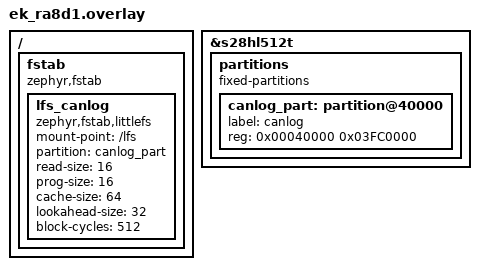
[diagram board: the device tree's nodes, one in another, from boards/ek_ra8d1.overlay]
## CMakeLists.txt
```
# SPDX-License-Identifier: Apache-2.0
#
# Phase 2D: littlefs on the Octo-SPI flash + batched CAN-frame logger
# (build-only, no board). Board target: ek_ra8d1. The littlefs partition and
# fstab node are defined in boards/ek_ra8d1.overlay (auto-applied by filename).

cmake_minimum_required(VERSION 3.28.0)

find_package(Zephyr REQUIRED HINTS $ENV{ZEPHYR_BASE})
project(flash_log)

target_include_directories(app PRIVATE include)
target_sources(app PRIVATE
  src/main.c
  src/flash_log.c
)
```

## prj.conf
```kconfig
# Phase 2D - littlefs on Octo-SPI flash + batched CAN logger. Every symbol
# checked against the workspace before being added.
#
#   CONFIG_FLASH               -> drivers/flash/Kconfig
#   CONFIG_FLASH_MAP           -> subsys/storage/flash_map/Kconfig. Required by
#                                 CONFIG_FS_LITTLEFS_FMP_DEV (littlefs on flash).
#   CONFIG_FLASH_PAGE_LAYOUT   -> drivers/flash/Kconfig:169. "default
#                                 FLASH_HAS_PAGE_LAYOUT"; the OSPI-B NOR driver
#                                 selects FLASH_HAS_PAGE_LAYOUT so this is
#                                 effectively automatic - set explicitly.
#   CONFIG_FLASH_RENESAS_RA_OSPI_B -> drivers/flash/Kconfig.renesas_ra_ospi.
#                                 "default y" when the &s28hl512t node
#                                 (compatible renesas,ra-ospi-b-nor) is enabled
#                                 by the board. Implements erase/write/read +
#                                 page_layout for the S28HX512T.
#   CONFIG_FILE_SYSTEM / _LITTLEFS -> subsys/fs/Kconfig + Kconfig.littlefs.
#                                 LITTLEFS needs the modules/fs/littlefs module
#                                 (present in this workspace).
#   CONFIG_RING_BUFFER        -> lib/os/Kconfig. SRAM staging ring in flash_log.c.
#   CONFIG_MAIN_STACK_SIZE=8192 -> fs_dirent / fs_statvfs plus the 1 KiB drain
#                                 buffer used by flash_log_stop() on the main
#                                 thread (the littlefs sample uses 4096 with no
#                                 extra stack buffers).

CONFIG_FLASH=y
CONFIG_FLASH_MAP=y
CONFIG_FLASH_PAGE_LAYOUT=y
CONFIG_FLASH_RENESAS_RA_OSPI_B=y

CONFIG_FILE_SYSTEM=y
CONFIG_FILE_SYSTEM_LITTLEFS=y

CONFIG_RING_BUFFER=y

CONFIG_MAIN_STACK_SIZE=8192

CONFIG_LOG=y
CONFIG_LOG_DEFAULT_LEVEL=3

# TEMP (bring-up diagnostic): surface which step of the OSPI SPI-mode init
# fails - the reasons are LOG_DBG inside flash_renesas_ra_ospi_b.c.
CONFIG_FLASH_LOG_LEVEL_DBG=y
```

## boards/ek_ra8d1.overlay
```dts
/*
 * App-local devicetree overlay for apps/flash_log on the EK-RA8D1.
 * Zephyr auto-applies <app>/boards/<board>.overlay by filename.
 *
 * Re-partitions the on-board 64 MB Octo-SPI NOR flash (U3, S28HL512T, node
 * &s28hl512t, controller &ospi0) for a littlefs log store. The stock board dts
 * gives it one whole-chip partition labelled "nor"; we replace that.
 *
 * Erase geometry (from the board node's pages_layout, verified in
 * zephyr/boards/renesas/ek_ra8d1/ek_ra8d1.dts):
 *     0x00000000 .. 0x00020000   32 x 4 KiB sectors
 *     0x00020000 .. 0x00040000   1 x 128 KiB sector
 *     0x00040000 .. 0x04000000   255 x 256 KiB sectors
 * Zephyr's littlefs flash backend uses the LARGEST page size that overlaps the
 * partition and assumes that erase size works across the whole partition
 * (subsys/fs/littlefs_fs.c get_block_size()). So the littlefs partition starts
 * at 0x40000 to sit entirely in the uniform 256 KiB-sector region; the first
 * 256 KiB is left unallocated (reserved for a future NVS/settings partition).
 */

&s28hl512t {
	/delete-node/ partitions;

	partitions {
		compatible = "fixed-partitions";
		#address-cells = <1>;
		#size-cells = <1>;

		canlog_part: partition@40000 {
			label = "canlog";
			/* 0x00040000 .. 0x04000000  (64 MiB - 256 KiB = 63.75 MiB) */
			reg = <0x00040000 0x03FC0000>;
		};
	};
};

/ {
	fstab {
		compatible = "zephyr,fstab";

		lfs_canlog: lfs_canlog {
			compatible = "zephyr,fstab,littlefs";
			mount-point = "/lfs";
			partition = <&canlog_part>;
			/* read/prog match the driver's write-block-size=1; cache 64
			 * is a factor of the 256 KiB block size and a multiple of
			 * prog-size, per the binding's constraints.
			 */
			read-size = <16>;
			prog-size = <16>;
			cache-size = <64>;
			lookahead-size = <32>;
			block-cycles = <512>;
			/* No `automount;` - flash_log.c mounts explicitly so it
			 * owns the mount/unmount lifecycle.
			 */
		};
	};
};
```

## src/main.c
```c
/*
 * SPDX-License-Identifier: Apache-2.0
 *
 * Phase 2D demo entry point (build-only, no board).
 *
 * Exercises the littlefs CAN logger so the whole module is compiled and
 * linked: mount -> start -> feed synthetic frames -> flush -> stop. None of
 * this runs without hardware (the OSPI flash and littlefs are never actually
 * touched in this session); there is no flashing in this phase.
 */

#include <errno.h>

#include <zephyr/kernel.h>
#include <zephyr/logging/log.h>

#include "flash_log.h"

LOG_MODULE_REGISTER(main, LOG_LEVEL_INF);

/* bit4 = RTR, matching flash_log_frame.flags / CAN_FRAME_* */
#define FRAME_FLAG_FDF 0x01
#define FRAME_FLAG_BRS 0x02

int main(void)
{
	struct flash_log_stats st;
	int ret;

	ret = flash_log_init();
	if (ret != 0) {
		LOG_ERR("flash_log_init failed: %d", ret);
		return 0;
	}

	ret = flash_log_start();
	if (ret != 0) {
		LOG_ERR("flash_log_start failed: %d", ret);
		return 0;
	}

	/* Simulate the "start logging" button having been pressed and a short
	 * burst of bus traffic arriving. flash_log_record() would normally be
	 * called from the CAN RX ISR (Phase 2A) with k_uptime_ticks() captured
	 * there.
	 */
	for (uint32_t i = 0; i < 200; i++) {
		struct flash_log_frame f = {
			.id = 0x100 + (i & 0x7F),
			.flags = FRAME_FLAG_FDF | FRAME_FLAG_BRS,
			.dlc = 8,
			.timestamp = k_uptime_ticks(),
		};

		for (int b = 0; b < 8; b++) {
			f.data[b] = (uint8_t)(i + b);
		}

		ret = flash_log_record(&f);
		if (ret == -ENOSPC) {
			LOG_WRN("ring full at frame %u (writer would catch up)", i);
		}
	}

	/* "Periodic flush trigger" (Phase 2B timer would call this). */
	flash_log_flush();
	k_sleep(K_MSEC(50));

	ret = flash_log_stop();
	if (ret != 0) {
		LOG_ERR("flash_log_stop failed: %d", ret);
	}

	flash_log_get_stats(&st);
	LOG_INF("stats: queued=%u dropped=%u bytes=%u flushes=%u werr=%u",
		st.records_queued, st.records_dropped, st.bytes_written,
		st.flush_count, st.write_errors);

	return 0;
}
```

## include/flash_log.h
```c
/*
 * SPDX-License-Identifier: Apache-2.0
 *
 * Phase 2D - persistent CAN-frame logger on the Octo-SPI flash (littlefs).
 *
 * Design points (see PROMPTS.md Phase 2D and STATE.md decisions):
 *   - Storage: littlefs on partition "canlog" of the on-board 64 MB OSPI NOR
 *     (&s28hl512t), mounted at /lfs. Partition + fstab node are in the app
 *     overlay.
 *   - Batched writes, NOT one flash write per frame: flash_log_record() only
 *     copies a serialised record into an SRAM ring buffer. A dedicated writer
 *     thread drains the ring to the open file in >= chunk-sized fs_write()s.
 *     This bounds flash wear and keeps the producer (a CAN RX ISR, later)
 *     non-blocking.
 *   - SRAM ring, not SDRAM: the board's 64 MB SDRAM is populated (SW1-7 ON by
 *     default) but the decisions log keeps the logger on on-chip SRAM unless
 *     SRAM proves insufficient for burst absorption. SDRAM stays a documented
 *     future option (bump FLASH_LOG_RING_SIZE and place the ring in the SDRAM
 *     region).
 *   - Lossy by design: a full ring drops the frame and counts it rather than
 *     stalling the caller.
 *
 * Independent of the Phase 2A/2B/2C modules - it only takes a plain frame
 * struct. Wiring flash_log_record() to the CAN RX path and flash_log_flush()
 * to the Phase 2B periodic timer is an integration step for when hardware is
 * available.
 *
 * On-disk format: see the "CLB1" description in flash_log.c.
 */

#ifndef FLASH_LOG_FLASH_LOG_H_
#define FLASH_LOG_FLASH_LOG_H_

#include <stdbool.h>
#include <stdint.h>

#ifdef __cplusplus
extern "C" {
#endif

/** SRAM staging ring size. Raise (and relocate to SDRAM) for heavier bursts. */
#define FLASH_LOG_RING_SIZE 8192

/**
 * @brief One CAN(-FD) frame to be logged.
 *
 * Field semantics match the Phase 2A struct canlog_frame and the Phase 2C
 * struct clp_can_frame (flags bits = Zephyr CAN_FRAME_*).
 */
struct flash_log_frame {
	uint32_t id;
	uint8_t  flags;       /* bit0 FDF, bit1 BRS, bit2 ESI, bit3 IDE, bit4 RTR */
	uint8_t  dlc;         /* raw DLC; byte count via the CAN-FD DLC table    */
	uint8_t  data[64];
	uint64_t timestamp;   /* k_uptime_ticks() sampled by the caller          */
};

struct flash_log_stats {
	uint32_t records_queued;   /* accepted into the ring        */
	uint32_t records_dropped;  /* ring full                     */
	uint32_t bytes_written;    /* bytes fs_write()n to the file */
	uint32_t flush_count;      /* fs_sync() calls               */
	uint32_t write_errors;     /* fs_write()/fs_sync() failures */
};

/**
 * @brief Mount the littlefs log store at /lfs and start the writer thread.
 *
 * @retval 0        mounted
 * @retval -ENODEV  flash device / partition not available
 * @retval <0       errno from fs_mount()
 */
int flash_log_init(void);

/**
 * @brief Open a new log file "/lfs/log_<uptime_ticks>.clb" and write its header.
 *
 * @retval 0         logging started
 * @retval -EALREADY a log file is already open
 * @retval <0        errno from fs_open()/fs_write()
 */
int flash_log_start(void);

/** @return true while a log file is open. */
bool flash_log_active(void);

/**
 * @brief Queue a frame for logging (non-blocking).
 *
 * @retval 0        queued
 * @retval -ENOSPC  ring full, frame dropped (counted)
 * @retval -EPERM   logging not started
 */
int flash_log_record(const struct flash_log_frame *f);

/** Ask the writer thread to drain the ring and fs_sync() now. Non-blocking. */
int flash_log_flush(void);

/**
 * @brief Drain the ring, fs_sync(), and close the current log file.
 *
 * @retval 0        stopped
 * @retval -EALREADY no log file open
 * @retval <0       errno from fs_close()
 */
int flash_log_stop(void);

void flash_log_get_stats(struct flash_log_stats *out);

#ifdef __cplusplus
}
#endif

#endif /* FLASH_LOG_FLASH_LOG_H_ */
```

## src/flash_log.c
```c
/*
 * SPDX-License-Identifier: Apache-2.0
 *
 * Phase 2D - littlefs CAN-frame logger. Build-only; nothing is flashed and the
 * filesystem is never actually mounted in this session (no board).
 *
 * On-disk format ("CLB1"), little-endian, one file per logging session:
 *
 *   File header (16 bytes):
 *     off 0  : magic  "CLB1"                (4 bytes)
 *     off 4  : format_version  u16          (= 1)
 *     off 6  : header_length   u16          (= 16)
 *     off 8  : start_timestamp u64          (k_uptime_ticks() at flash_log_start)
 *
 *   Then a stream of variable-length records:
 *     off 0  : marker  u8   (= 0xC5, lets an offline tool resync)
 *     off 1  : flags   u8   (CAN_FRAME_* bits: FDF|BRS|ESI|IDE|RTR)
 *     off 2  : dlc     u8   (raw DLC)
 *     off 3  : n       u8   (data byte count = dlc_to_bytes(dlc), 0 if RTR)
 *     off 4  : can_id  u32
 *     off 8  : timestamp u64
 *     off 16 : data    n bytes
 *   record length = 16 + n.
 */

#include <errno.h>
#include <stdio.h>
#include <string.h>

#include <zephyr/kernel.h>
#include <zephyr/fs/fs.h>
#include <zephyr/fs/littlefs.h>
#include <zephyr/sys/byteorder.h>
#include <zephyr/sys/ring_buffer.h>
#include <zephyr/logging/log.h>

#include "flash_log.h"

LOG_MODULE_REGISTER(flash_log, LOG_LEVEL_INF);

/* fstab node from boards/ek_ra8d1.overlay. */
FS_FSTAB_DECLARE_ENTRY(DT_NODELABEL(lfs_canlog));
#define LOG_MP (&FS_FSTAB_ENTRY(DT_NODELABEL(lfs_canlog)))

BUILD_ASSERT(DT_NODE_EXISTS(DT_NODELABEL(lfs_canlog)),
	     "missing lfs_canlog fstab node - check the app overlay");

#define WRITE_CHUNK       1024U   /* max bytes per fs_write() batch  */
#define WRITER_IDLE_MS    500     /* drain accumulated data this often */
#define WRITER_STACK_SIZE 6144
#define STOP_WAIT_MS      2000

#define REC_MARKER 0xC5U
#define REC_FIXED  16U           /* marker+flags+dlc+n + id(4) + ts(8) */

RING_BUF_DECLARE(log_rb, FLASH_LOG_RING_SIZE);
static struct k_spinlock rb_lock;

static struct fs_file_t log_file;
static K_MUTEX_DEFINE(file_lock);
static atomic_t active;
static atomic_t flush_req;
static atomic_t mounted;

static K_SEM_DEFINE(wake, 0, 1);

/* producer-updated */
static atomic_t stat_queued;
static atomic_t stat_dropped;
/* writer-thread-updated (single writer + the stop path, serialised by file_lock) */
static uint32_t stat_bytes;
static uint32_t stat_flush;
static uint32_t stat_werr;

/* CAN-FD DLC -> byte count (local copy; no <zephyr/drivers/can.h> dependency). */
static uint8_t dlc_to_bytes(uint8_t dlc)
{
	static const uint8_t tbl[16] = {
		0, 1, 2, 3, 4, 5, 6, 7, 8, 12, 16, 20, 24, 32, 48, 64,
	};
	return tbl[dlc & 0x0FU];
}

static uint32_t rb_get_locked(uint8_t *buf, uint32_t size)
{
	k_spinlock_key_t key = k_spin_lock(&rb_lock);
	uint32_t n = ring_buf_get(&log_rb, buf, size);

	k_spin_unlock(&rb_lock, key);
	return n;
}

static uint32_t rb_size_locked(void)
{
	k_spinlock_key_t key = k_spin_lock(&rb_lock);
	uint32_t n = ring_buf_size_get(&log_rb);

	k_spin_unlock(&rb_lock, key);
	return n;
}

/* Drain the ring to the open file. Caller holds file_lock and has confirmed a
 * file is open. @p min_bytes: only write once at least this many bytes are
 * queued (WRITE_CHUNK for the steady state, 1 to fully drain).
 */
static void drain_to_file(uint8_t *buf, uint32_t min_bytes)
{
	while (rb_size_locked() >= min_bytes) {
		uint32_t n = rb_get_locked(buf, WRITE_CHUNK);
		ssize_t w;

		if (n == 0U) {
			break;
		}

		w = fs_write(&log_file, buf, n);
		if (w < 0) {
			LOG_ERR("fs_write failed: %d", (int)w);
			stat_werr++;
			break;
		}
		stat_bytes += (uint32_t)w;

		if ((uint32_t)w < n) {
			/* Short write - return the tail to the ring and stop. */
			k_spinlock_key_t key = k_spin_lock(&rb_lock);

			ring_buf_put(&log_rb, &buf[w], n - (uint32_t)w);
			k_spin_unlock(&rb_lock, key);
			break;
		}
	}
}

static void writer_fn(void *a, void *b, void *c)
{
	ARG_UNUSED(a);
	ARG_UNUSED(b);
	ARG_UNUSED(c);

	uint8_t buf[WRITE_CHUNK];

	for (;;) {
		bool flush;

		(void)k_sem_take(&wake, K_MSEC(WRITER_IDLE_MS));
		flush = atomic_set(&flush_req, 0) != 0;

		k_mutex_lock(&file_lock, K_FOREVER);
		if (atomic_get(&active)) {
			drain_to_file(buf, flush ? 1U : WRITE_CHUNK);

			if (flush && fs_sync(&log_file) == 0) {
				stat_flush++;
			} else if (flush) {
				stat_werr++;
			}
		}
		k_mutex_unlock(&file_lock);
	}
}

K_THREAD_DEFINE(flash_log_writer, WRITER_STACK_SIZE, writer_fn, NULL, NULL, NULL,
		K_PRIO_PREEMPT(7), 0, 0);

/* -------------------------------------------------------------------------- */

int flash_log_init(void)
{
	int rc;

	if (atomic_get(&mounted)) {
		return 0;
	}

	fs_file_t_init(&log_file);

	rc = fs_mount(LOG_MP);
	if (rc < 0) {
		LOG_ERR("fs_mount(%s) failed: %d", LOG_MP->mnt_point, rc);
		return rc;
	}

	atomic_set(&mounted, 1);
	LOG_INF("littlefs mounted at %s", LOG_MP->mnt_point);

	struct fs_statvfs sb;

	if (fs_statvfs(LOG_MP->mnt_point, &sb) == 0) {
		LOG_INF("  bsize=%lu frsize=%lu blocks=%lu bfree=%lu",
			sb.f_bsize, sb.f_frsize, sb.f_blocks, sb.f_bfree);
	}
	return 0;
}

int flash_log_start(void)
{
	char name[40];
	uint8_t hdr[16];
	int rc;

	if (!atomic_get(&mounted)) {
		return -ENODEV;
	}

	k_mutex_lock(&file_lock, K_FOREVER);
	if (atomic_get(&active)) {
		k_mutex_unlock(&file_lock);
		return -EALREADY;
	}

	snprintf(name, sizeof(name), "%s/log_%llu.clb", LOG_MP->mnt_point,
		 (unsigned long long)k_uptime_ticks());

	rc = fs_open(&log_file, name, FS_O_CREATE | FS_O_WRITE);
	if (rc < 0) {
		LOG_ERR("fs_open(%s) failed: %d", name, rc);
		k_mutex_unlock(&file_lock);
		return rc;
	}

	memcpy(&hdr[0], "CLB1", 4);
	sys_put_le16(1, &hdr[4]);
	sys_put_le16(sizeof(hdr), &hdr[6]);
	sys_put_le64(k_uptime_ticks(), &hdr[8]);

	rc = fs_write(&log_file, hdr, sizeof(hdr));
	if (rc < 0) {
		LOG_ERR("header write failed: %d", rc);
		(void)fs_close(&log_file);
		k_mutex_unlock(&file_lock);
		return rc;
	}
	stat_bytes += (uint32_t)rc;

	atomic_set(&active, 1);
	k_mutex_unlock(&file_lock);

	LOG_INF("logging to %s", name);
	return 0;
}

bool flash_log_active(void)
{
	return atomic_get(&active) != 0;
}

int flash_log_record(const struct flash_log_frame *f)
{
	uint8_t rec[REC_FIXED + 64];
	uint8_t n;
	uint32_t wrote;
	k_spinlock_key_t key;

	if (!atomic_get(&active)) {
		return -EPERM;
	}

	n = dlc_to_bytes(f->dlc);
	if ((f->flags & BIT(4)) != 0U) { /* RTR: no data */
		n = 0U;
	}

	rec[0] = REC_MARKER;
	rec[1] = f->flags;
	rec[2] = f->dlc;
	rec[3] = n;
	sys_put_le32(f->id, &rec[4]);
	sys_put_le64(f->timestamp, &rec[8]);
	memcpy(&rec[REC_FIXED], f->data, n);

	key = k_spin_lock(&rb_lock);
	if (ring_buf_space_get(&log_rb) < (uint32_t)(REC_FIXED + n)) {
		k_spin_unlock(&rb_lock, key);
		atomic_inc(&stat_dropped);
		return -ENOSPC;
	}
	wrote = ring_buf_put(&log_rb, rec, REC_FIXED + n);
	k_spin_unlock(&rb_lock, key);

	if (wrote != (uint32_t)(REC_FIXED + n)) {
		atomic_inc(&stat_dropped);
		return -ENOSPC;
	}

	atomic_inc(&stat_queued);

	/* Nudge the writer once the ring is half full. */
	if (rb_size_locked() >= (FLASH_LOG_RING_SIZE / 2U)) {
		k_sem_give(&wake);
	}
	return 0;
}

int flash_log_flush(void)
{
	if (!atomic_get(&active)) {
		return -EPERM;
	}
	atomic_set(&flush_req, 1);
	k_sem_give(&wake);
	return 0;
}

int flash_log_stop(void)
{
	uint8_t buf[WRITE_CHUNK];
	int rc;

	k_mutex_lock(&file_lock, K_FOREVER);
	if (!atomic_get(&active)) {
		k_mutex_unlock(&file_lock);
		return -EALREADY;
	}
	k_mutex_unlock(&file_lock);

	/* Let the writer drain what it can. */
	atomic_set(&flush_req, 1);
	k_sem_give(&wake);
	for (int i = 0; i < (STOP_WAIT_MS / 50) && rb_size_locked() > 0U; i++) {
		k_sleep(K_MSEC(50));
	}

	/* Take ownership, drain the remainder synchronously, close. */
	k_mutex_lock(&file_lock, K_FOREVER);
	atomic_set(&active, 0);
	drain_to_file(buf, 1U);
	(void)fs_sync(&log_file);
	stat_flush++;
	rc = fs_close(&log_file);
	k_mutex_unlock(&file_lock);

	if (rc < 0) {
		LOG_ERR("fs_close failed: %d", rc);
		return rc;
	}
	LOG_INF("logging stopped (%u bytes written)", stat_bytes);
	return 0;
}

void flash_log_get_stats(struct flash_log_stats *out)
{
	out->records_queued = (uint32_t)atomic_get(&stat_queued);
	out->records_dropped = (uint32_t)atomic_get(&stat_dropped);
	out->bytes_written = stat_bytes;
	out->flush_count = stat_flush;
	out->write_errors = stat_werr;
}
```
